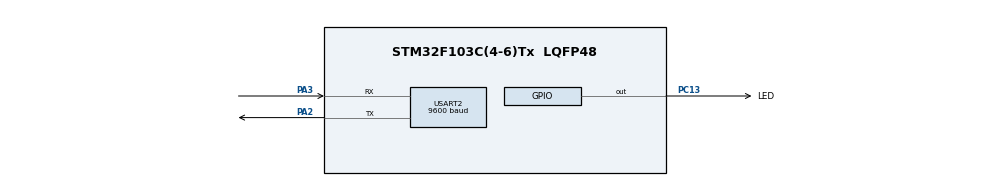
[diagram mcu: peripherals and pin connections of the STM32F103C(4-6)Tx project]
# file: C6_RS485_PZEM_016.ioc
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Mcu.Family=STM32F1
Mcu.Name=STM32F103C(4-6)Tx
Mcu.Package=LQFP48
NVIC.PriorityGroup=NVIC_PRIORITYGROUP_4
NVIC.USART2_IRQn=true\:0\:0\:false\:false\:true\:true\:true
PA13.Mode=Serial_Wire
PA13.Signal=SYS_JTMS-SWDIO
PA14.Mode=Serial_Wire
PA14.Signal=SYS_JTCK-SWCLK
PA2.Mode=Asynchronous
PA2.Signal=USART2_TX
PA3.Mode=Asynchronous
PA3.Signal=USART2_RX
PC13-TAMPER-RTC.GPIO_Label=LED
PC13-TAMPER-RTC.Signal=GPIO_Output
PD0-OSC_IN.Mode=HSE-External-Oscillator
PD0-OSC_IN.Signal=RCC_OSC_IN
PD1-OSC_OUT.Mode=HSE-External-Oscillator
PD1-OSC_OUT.Signal=RCC_OSC_OUT
ProjectManager.HeapSize=0x200
ProjectManager.StackSize=0x400
ProjectManager.TargetToolchain=STM32CubeIDE
RCC.APB1Freq_Value=8000000
RCC.APB2Freq_Value=8000000
USART2.BaudRate=9600
USART2.VirtualMode=VM_ASYNC
board=custom

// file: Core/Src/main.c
/* USER CODE BEGIN Header */
/**
 ******************************************************************************
 * @file           : main.c
 * @brief          : Main program body
 ******************************************************************************
 * @attention
 *
 * <h2><center>&copy; Copyright (c) 2023 STMicroelectronics.
 * All rights reserved.</center></h2>
 *
 * This software component is licensed by ST under BSD 3-Clause license,
 * the "License"; You may not use this file except in compliance with the
 * License. You may obtain a copy of the License at:
 *                        opensource.org/licenses/BSD-3-Clause
 *
 ******************************************************************************
 */
/* USER CODE END Header */
#include "main.h"

/* USER CODE BEGIN Includes */
#include "modbus_crc.h"
#include "string.h"
#include "stdio.h"
/* USER CODE END Includes */

UART_HandleTypeDef huart2;

void SystemClock_Config(void);
static void MX_GPIO_Init(void);
static void MX_USART2_UART_Init(void);

/* USER CODE BEGIN 0 */
#define DataSizeRx 32
#define DataSizeTx 8
#define DataSizeValue 10

uint8_t RxData[DataSizeRx];
uint8_t TxData[DataSizeTx];
uint8_t Data[DataSizeValue];
uint8_t flag = 0;
uint8_t len;
void HAL_UARTEx_RxEventCallback(UART_HandleTypeDef *huart, uint16_t Size) {

	Data[0] = RxData[3] << 8 | RxData[4];		// 0b 0000 0000 0000 0000 0000 0000 0000 0000
	Data[1] = RxData[5] << 8 | RxData[6];
	Data[2] = RxData[9] << 8 | RxData[10];
	Data[3] = RxData[13] << 8 | RxData[14];
	Data[4] = RxData[17] << 8 | RxData[18];
	Data[5] = RxData[19] << 8 | RxData[20];
	len = Size;
	flag = 1;
	HAL_UARTEx_ReceiveToIdle_IT(&huart2, RxData, DataSizeRx);
}
void SendData(uint8_t *Data) {
	HAL_UART_Transmit(&huart2, Data, 8, 1000);
}
/* USER CODE END 0 */

int main(void) {

	/* MCU Configuration--------------------------------------------------------*/

	/* Reset of all peripherals, Initializes the Flash interface and the Systick. */
	HAL_Init();

	/* Configure the system clock */
	SystemClock_Config();

	/* Initialize all configured peripherals */
	MX_GPIO_Init();
	MX_USART2_UART_Init();
	/* USER CODE BEGIN 2 */
	HAL_UARTEx_ReceiveToIdle_IT(&huart2, RxData, DataSizeRx);

	TxData[0] = 0x01;  // slave address
	TxData[1] = 0x04;  // Function code for Read Holding Registers
	TxData[2] = 0x00;			// address begin 4001
	TxData[3] = 0x00;		// 4001 + 0x01 = 4002
	TxData[4] = 0x00;			// 0x00
	TxData[5] = 0x0A;		// 0x00 + 0x05 = 5 registers
	/// 0x00 0x03 0x00 0x01 0x00 0x05 -> read address 4002  ->> 4006 ///
	uint16_t crc = crc16(TxData, 6);
	TxData[6] = crc & 0xFF;   // CRC LOW
	TxData[7] = (crc >> 8) & 0xFF;  // CRC HIGH
	SendData(TxData);
	/* USER CODE END 2 */

	/* Infinite loop */
	/* USER CODE BEGIN WHILE */
	while (1) {
		static uint32_t t_prev = 0;
		if (HAL_GetTick() - t_prev >= 1000) {
			HAL_GPIO_TogglePin(LED_GPIO_Port, LED_Pin);
			SendData(TxData);
			t_prev = HAL_GetTick();
		}
		if (flag == 1) {

//			Data[0] = RxData[3] * 256 + RxData[4];
//			Data[1] = RxData[5] * 256 + RxData[6];
//			Data[3] = RxData[9] * 256 + RxData[10];
//			Data[5] = RxData[13] * 256 + RxData[14];
//			Data[7] = RxData[17] * 256 + RxData[18];
//			Data[8] = RxData[19] * 256 + RxData[20];
			memset(RxData, 0, strlen((char*) RxData));
			flag = 0;
		}
		/* USER CODE END WHILE */

	}
}

void SystemClock_Config(void) {
	RCC_OscInitTypeDef RCC_OscInitStruct = { 0 };
	RCC_ClkInitTypeDef RCC_ClkInitStruct = { 0 };

	/** Initializes the RCC Oscillators according to the specified parameters
	 * in the RCC_OscInitTypeDef structure.
	 */
	RCC_OscInitStruct.OscillatorType = RCC_OSCILLATORTYPE_HSI;
	RCC_OscInitStruct.HSIState = RCC_HSI_ON;
	RCC_OscInitStruct.HSICalibrationValue = RCC_HSICALIBRATION_DEFAULT;
	RCC_OscInitStruct.PLL.PLLState = RCC_PLL_NONE;
	if (HAL_RCC_OscConfig(&RCC_OscInitStruct) != HAL_OK) {
		Error_Handler();
	}
	/** Initializes the CPU, AHB and APB buses clocks
	 */
	RCC_ClkInitStruct.ClockType = RCC_CLOCKTYPE_HCLK | RCC_CLOCKTYPE_SYSCLK
			| RCC_CLOCKTYPE_PCLK1 | RCC_CLOCKTYPE_PCLK2;
	RCC_ClkInitStruct.SYSCLKSource = RCC_SYSCLKSOURCE_HSI;
	RCC_ClkInitStruct.AHBCLKDivider = RCC_SYSCLK_DIV1;
	RCC_ClkInitStruct.APB1CLKDivider = RCC_HCLK_DIV1;
	RCC_ClkInitStruct.APB2CLKDivider = RCC_HCLK_DIV1;

	if (HAL_RCC_ClockConfig(&RCC_ClkInitStruct, FLASH_LATENCY_0) != HAL_OK) {
		Error_Handler();
	}
}

static void MX_USART2_UART_Init(void) {

	huart2.Instance = USART2;
	huart2.Init.BaudRate = 9600;
	huart2.Init.WordLength = UART_WORDLENGTH_8B;
	huart2.Init.StopBits = UART_STOPBITS_1;
	huart2.Init.Parity = UART_PARITY_NONE;
	huart2.Init.Mode = UART_MODE_TX_RX;
	huart2.Init.HwFlowCtl = UART_HWCONTROL_NONE;
	huart2.Init.OverSampling = UART_OVERSAMPLING_16;
	if (HAL_UART_Init(&huart2) != HAL_OK) {
		Error_Handler();
	}

}

static void MX_GPIO_Init(void) {
	GPIO_InitTypeDef GPIO_InitStruct = { 0 };

	/* GPIO Ports Clock Enable */
	__HAL_RCC_GPIOC_CLK_ENABLE();
	__HAL_RCC_GPIOD_CLK_ENABLE();
	__HAL_RCC_GPIOA_CLK_ENABLE();

	/*Configure GPIO pin Output Level */
	HAL_GPIO_WritePin(LED_GPIO_Port, LED_Pin, GPIO_PIN_RESET);

	/*Configure GPIO pin : LED_Pin */
	GPIO_InitStruct.Pin = LED_Pin;
	GPIO_InitStruct.Mode = GPIO_MODE_OUTPUT_PP;
	GPIO_InitStruct.Pull = GPIO_NOPULL;
	GPIO_InitStruct.Speed = GPIO_SPEED_FREQ_LOW;
	HAL_GPIO_Init(LED_GPIO_Port, &GPIO_InitStruct);

}

void Error_Handler(void) {
	__disable_irq();
	while (1) {
	}
}

/************************ (C) COPYRIGHT STMicroelectronics *****END OF FILE****/
